# D2522AA register map
Vendor: Dialog; Series: D2522AA; File version: 1.2
CPU: CM0 r1p0, little endian, MPU, FPU, 3 interrupt priority bits
Registers are 32-bit, read-write, reset 0x0 unless marked. A register's access mark holds for its fields unless they carry their own. Offsets are from the block's base; [hi:lo] are bit positions; {n}, {i} and the like mark numbered series; <NAME> marks a mode.

## CRG_TOP — CRG_TOP registers
Base 0x50000000
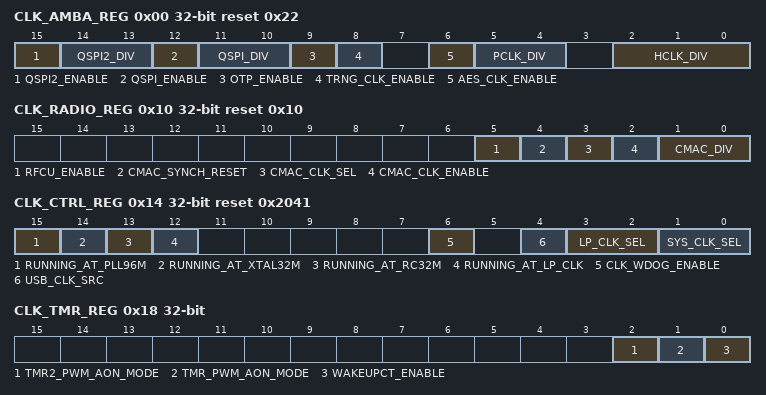
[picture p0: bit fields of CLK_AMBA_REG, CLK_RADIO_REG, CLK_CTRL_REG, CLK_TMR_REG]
0x00 CLK_AMBA_REG reset 0x22 — HCLK, PCLK, divider and clock gates
  [15] QSPI2_ENABLE — Clock enable for QSPI RAM controller
  [14:13] QSPI2_DIV — QSPI divider 00 = divide by 1 01 = divide by 2 10 = divide by 4 11 = divide by 8
  [12] QSPI_ENABLE — Clock enable for QSPI controller
  [11:10] QSPI_DIV — QSPI divider 00 = divide by 1 01 = divide by 2 10 = divide by 4 11 = divide by 8
  [9] OTP_ENABLE — Clock enable for OTP controller
  [8] TRNG_CLK_ENABLE — Clock enable for TRNG block
  [6] AES_CLK_ENABLE — Clock enable for AES crypto block
  [5:4] PCLK_DIV — APB interface clock, Cascaded with HCLK: 00 = divide hclk by 1 01 = divide hclk by 2 10 = divide hclk by 4 11 = divide hclk by 8
  [2:0] HCLK_DIV — AHB interface and microprocessor clock. Source clock divided by: 000 = divide hclk by 1 001 = divide hclk by 2 010 = divide hclk by 4 011 = divide hclk by 8 1xx = divide hclk by 16
0x10 CLK_RADIO_REG reset 0x10 — Radio PLL control register
  [5] RFCU_ENABLE — Enable the RF control Unit clock
  [4] CMAC_SYNCH_RESET — Force synchronous reset to CMAC core and Sleep Timer. Its effective only when both Radio and Timer Power Domains are powered and the clocks are enabled. CMAC CPU and CMAC registers, including the retained ones, will be reset. The 1 should be kept for enough time to make sure that it will be captured by CMAC, Low Power and APB clocks. Should be kept to 1 at least until CM_SLP_SYS_REG->CMAC_RST_BS = 1. To avoid issues with CMAC CPU Debugger its recommended to keep the resetting period short.
  [3] CMAC_CLK_SEL — Selects the clock source 1 = DIV1 clock 0 = DIVN clock
  [2] CMAC_CLK_ENABLE — Enables the clock
  [1:0] CMAC_DIV — Division factor for CMAC 0x0 = divide by 1 0x1 = divide by 2 0x2 = divide by 4 0x3 = divide by 8
0x14 CLK_CTRL_REG reset 0x2041 — Clock control register
  [15] RUNNING_AT_PLL96M ro — Indicates that the PLL96MHz clock is used as clock, and may not be switched off
  [14] RUNNING_AT_XTAL32M ro — Indicates that the XTAL32M clock is used as clock, and may not be switched off
  [13] RUNNING_AT_RC32M ro — Indicates that the RC32M clock is used as clock
  [12] RUNNING_AT_LP_CLK ro — Indicates that either the LP_CLK is being used as clock
  [6] CLK_WDOG_ENABLE — Enables the CLOCK watchdog
  [4] USB_CLK_SRC — Selects the USB source clock 0 : PLL clock, divided by 2 1 : HCLK
  [3:2] LP_CLK_SEL — Sets the clock source of the LowerPower clock 0x0: RC32K 0x1: RCX 0x2: XTAL32K through the oscillator with an external Crystal. 0x3: XTAL32K through an external square wave generator (set PID of GPIO to FUNC_GPIO)
  [1:0] SYS_CLK_SEL — Selects the clock source. 0x0 : XTAL32M 0x1 : RC32M 0x2 : The Low Power clock is used 0x3 : The PLL96Mhz is used
    0=XTAL16M (Selects the XTAL16M as source clock); 1=RC16M (Selects the RC16M as source clock); 2=LP_CLK (Selects the LP_CLK, defined by CLK32K_SOURCE); 3=PLL96M (Selects the PLL96M as source clock)
0x18 CLK_TMR_REG — Clock control for the timers
  [2] TMR2_PWM_AON_MODE — Maps Timer2_pwm onto P1_06. This state is preserved during deep sleep, to allow PWM output on the pad during deep sleep.
  [1] TMR_PWM_AON_MODE — Maps Timer1_pwm onto P1_01 This state is preserved during deep sleep, to allow PWM output on the pad during deep sleep.
  [0] WAKEUPCT_ENABLE — Enables the clock
0x1C CLK_SWITCH2XTAL_REG — Switches clock from RC32M to XTAL32M
  [0] SWITCH2XTAL wo — When writing to this register, the clock switch will happen from RC32M to XTAL32M. If any other clock is selected than RC32M, the selection is discarded.
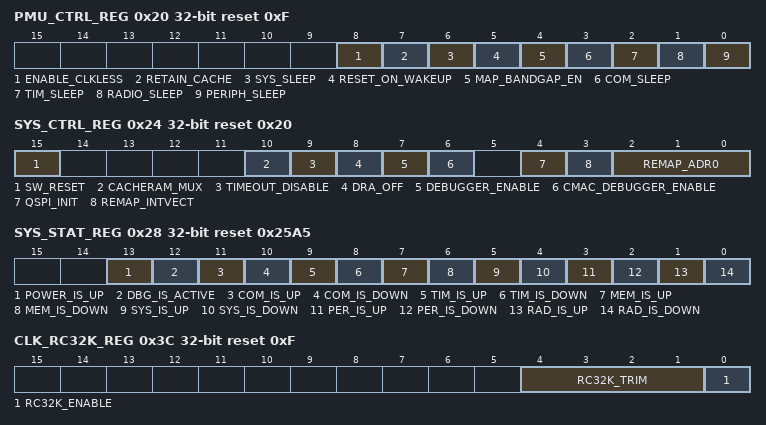
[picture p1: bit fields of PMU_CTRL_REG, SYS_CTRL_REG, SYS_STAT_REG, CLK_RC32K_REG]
0x20 PMU_CTRL_REG reset 0xF — Power Management Unit control register
  [8] ENABLE_CLKLESS — Selects the clockless sleep mode. Wakeup is done asynchronously. When set to '1', the lp_clk is stopped during deep sleep, until a wakeup event (not debounced) is detected by the WAKUPCT block. When set to '0', the lp_clk continues running, so the MAC counters keep on running. This mode cannot be combined with regulated sleep, so keep SLEEP_TIMER=0 when using ENABLE_CLKLESS.
  [7] RETAIN_CACHE — Selects the retainability of the cache block during deep sleep. '1' is retainable, '0' is power gated
  [6] SYS_SLEEP — Put the System powerdomain (PD_SYS) in powerdown. If this bit is '1', and there is no pending IRQ in the PDC for the M33, the PD_SYS will be switched off. Wakeup should be handled by the PDC.
  [5] RESET_ON_WAKEUP — Perform a Hardware Reset after waking up. Booter will be started.
  [4] MAP_BANDGAP_EN — Maps the bandgap_enable to P06
  [3] COM_SLEEP — Put the Communications powerdomain (PD_COM) in powerdown
  [2] TIM_SLEEP — Put the Timers Powerdomain (PD_TIM) in powerdown.
  [1] RADIO_SLEEP — Put the digital part of the radio, including CMAC (PD_RAD) in powerdown
  [0] PERIPH_SLEEP — Put the peripherals power domain (PD_PER) in powerdown
0x24 SYS_CTRL_REG reset 0x20 — System Control register
  [15] SW_RESET wo — Writing a '1' to this bit will generate a SW_RESET.
  [10] CACHERAM_MUX — Controls accessiblity of Cache RAM: 0: the cache controller is bypassed, the cacheRAM is visible in the memory space next to the DataRAMs 1: the cache controller is enabled, the cacheRAM is not visible anymore in the memory space
  [9] TIMEOUT_DISABLE — Disables timeout in Power statemachine. By default, the statemachine continues if after 2 ms the blocks are not started up. This can be read back from ANA_STATUS_REG
  [8] DRA_OFF — Disables the DRA mode, and released the ARM reset
  [7] DEBUGGER_ENABLE — Enable the debugger. This bit is set by the booter according to the OTP header. If not set, the SWDIO and SW_CLK can be used as gpio ports.
  [6] CMAC_DEBUGGER_ENABLE — Enable the CMAC debugger. This bit is set by the booter according to the OTP header. If not set, the SWDIO and SW_CLK can be used as gpio ports.
  [4] QSPI_INIT — Enables QSPI initialization after wakeup
  [3] REMAP_INTVECT — 0: normal operation 1: If ARM is in address range 0 to 0x1FF then the address is remapped to SYS-RAM 0x07FC.0000 to 0x07FC.01FF. This allows to put the interrupt vector table to be placed in RAM while executing from QSPI
  [2:0] REMAP_ADR0 — Controls which memory is located at address 0x0000 for execution. 0x0: ROM 0x1: OTP un-cached 0x2: QSPI FLASH cached 0x3: RAMS un-cached 0x4: QSPI FLASH un-cached (for verification only) 0x5: Reserved 0x6: Cache Data RAM un-cached (CACHERAM_MUX=0, for testing purposes only) Note 1: DWord (64 bits) access is not supported by the Cache Data RAM interface in mirrored mode (only 32, 16 and 8 bits). Note 2: DMA access is not supported by the Cache Data RAM interface when REMAP_ADR0=0x6.
0x28 SYS_STAT_REG reset 0x25A5 — System status register
  [13] POWER_IS_UP ro — Indicates that the Startup statemachine is finished, and all power regulation is in order. In UltraFastWakeup mode, the SW needs to wait for this signal before starting any heavy traffic.
  [12] DBG_IS_ACTIVE ro — Indicates that a debugger is attached.
  [11] COM_IS_UP ro — Indicates that PD_COM is functional
  [10] COM_IS_DOWN ro — Indicates that PD_COM is in power down
  [9] TIM_IS_UP ro — Indicates that PD_TIM is functional
  [8] TIM_IS_DOWN ro — Indicates that PD_TIM is in power down
  [7] MEM_IS_UP ro — Indicates that PD_MEM is functional
  [6] MEM_IS_DOWN ro — Indicates that PD_MEM is power down
  [5] SYS_IS_UP ro — Indicates that PD_PER is functional
  [4] SYS_IS_DOWN ro — Indicates that PD_PER is in power down
  [3] PER_IS_UP ro — Indicates that PD_PER is functional
  [2] PER_IS_DOWN ro — Indicates that PD_PER is in power down
  [1] RAD_IS_UP ro — Indicates that PD_RAD is functional
  [0] RAD_IS_DOWN ro — Indicates that PD_RAD is in power down
0x3C CLK_RC32K_REG reset 0xF — 32 kHz RC oscillator register
  [4:1] RC32K_TRIM — 0000 = lowest frequency 0111 = default 1111 = highest frequency
  [0] RC32K_ENABLE — Enables the 32kHz RC oscillator
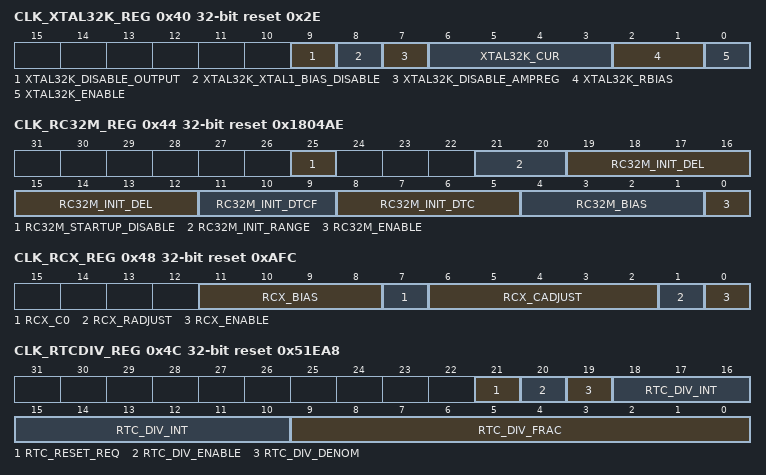
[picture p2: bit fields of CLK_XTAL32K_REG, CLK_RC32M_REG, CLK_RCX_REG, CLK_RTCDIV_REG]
0x40 CLK_XTAL32K_REG reset 0x2E — 32 kHz XTAL oscillator register
  [9] XTAL32K_DISABLE_OUTPUT — Disables output buffer, test only
  [8] XTAL32K_XTAL1_BIAS_DISABLE — Disables the 1nA bias current through the pull down diode
  [7] XTAL32K_DISABLE_AMPREG — Setting this bit disables the amplitude regulation of the XTAL32kHz oscillator. Set this bit to '1' for an external clock to XTAL32Kp Keep this bit '0' with a crystal between XTAL32Kp and XTAL32Km
  [6:3] XTAL32K_CUR — Bias current for the 32kHz XTAL oscillator. 0000 is minimum, 1111 is maximum, 0011 is default. For each application there is an optimal setting for which the start-up behavior is optimal
  [2:1] XTAL32K_RBIAS — Setting for the bias resistor. 00 is maximum, 11 is minimum. Prefered setting will be provided by Dialog
  [0] XTAL32K_ENABLE — Enables the 32kHz XTAL oscillator
0x44 CLK_RC32M_REG reset 0x1804AE — Fast RC control register
  [25] RC32M_STARTUP_DISABLE — Gates the RC32 enable from the startup block. The enable from the clksel and CLK_RC32M_REG[0] are not gated by this bit.
  [21:20] RC32M_INIT_RANGE — Course frequency adjustment
  [19:12] RC32M_INIT_DEL — Fine frequency adjustment
  [11:9] RC32M_INIT_DTCF — Fine duty-cycle adjustment. 0x0: minimum 0x2: default 0x4: maximum
  [8:5] RC32M_INIT_DTC — Course duty-cycle adjustment. 0x0: minimum 0x5: default 0xA: maximum
  [4:1] RC32M_BIAS — Bias adjustment
  [0] RC32M_ENABLE — Enables the 32MHz RC oscillator
0x48 CLK_RCX_REG reset 0xAFC — RCX-oscillator control register
  [11:8] RCX_BIAS — LDO bias current. 0x0: minimum 0xF: maximum
  [7] RCX_C0 — Add unit capacitance to RC-time delay.
  [6:2] RCX_CADJUST — Adjust capacitance part of RC-time delay. 0x00: minimum capacitance 0x1F: maximum capacitance
  [1] RCX_RADJUST — Adjust resistance part of RC-time delay. Lower resistance increases power consumption. 0x0: maximum resistance 0x1: minimum resistance
  [0] RCX_ENABLE — Enable the RCX oscillator
0x4C CLK_RTCDIV_REG reset 0x51EA8 — Divisor for RTC 100Hz clock
  [21] RTC_RESET_REQ — Reset request for the RTC module
  [20] RTC_DIV_ENABLE — Enable for the 100 Hz generation for the RTC block
  [19] RTC_DIV_DENOM — Selects the denominator for the fractional division: 0b0: 1000 0b1: 1024
  [18:10] RTC_DIV_INT — Integer divisor part for RTC 100Hz generation
  [9:0] RTC_DIV_FRAC — Fractional divisor part for RTC 100Hz generation. if RTC_DIV_DENOM=1, <RTC_DIV_FRAC> out of 1024 cycles will divide by <RTC_DIV_INT+1>, the rest is <RTC_DIV_INT> If RTC_DIV_DENOM=0, <RTC_DIV_FRAC> out of 1000 cycles will divide by <RTC_DIV_INT+1>, the rest is <RTC_DIV_INT>
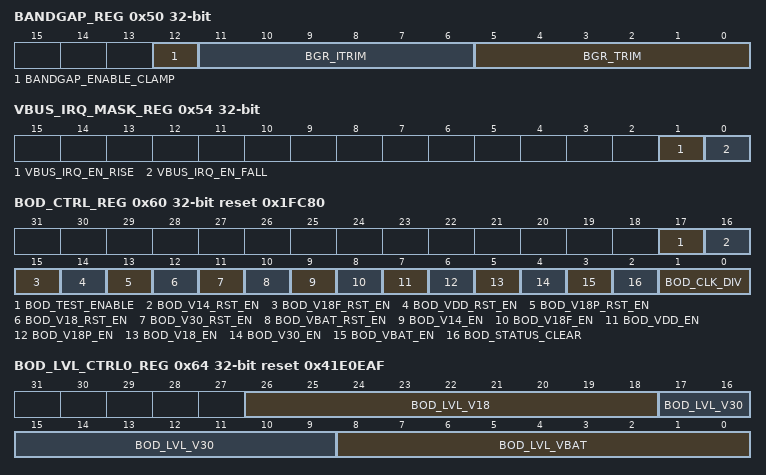
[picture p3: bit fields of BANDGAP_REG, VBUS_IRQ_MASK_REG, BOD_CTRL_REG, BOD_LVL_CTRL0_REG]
0x50 BANDGAP_REG — bandgap trimming
  [12] BANDGAP_ENABLE_CLAMP — Enables a supply clamp inside the bandgap that improves PSRR. Should be enabled by software after cold boot.
  [11:6] BGR_ITRIM — Current trimming for bias
  [5:0] BGR_TRIM — Trim register for bandgap
0x54 VBUS_IRQ_MASK_REG — IRQ masking
  [1] VBUS_IRQ_EN_RISE — Setting this bit to '1' enables VBUS_IRQ generation when the VBUS starts to ramp above threshold
  [0] VBUS_IRQ_EN_FALL — Setting this bit to '1' enables VBUS_IRQ generation when the VBUS starts to fall below threshold
0x58 VBUS_IRQ_CLEAR_REG — Clear pending IRQ register
  [15:0] VBUS_IRQ_CLEAR wo — Writing any value to this register will reset the VBUS_IRQ line
0x60 BOD_CTRL_REG reset 0x1FC80 — Brown Out Detection control register
  [17] BOD_TEST_ENABLE
  [16] BOD_V14_RST_EN — If set, generate power-on reset on channel V14
  [15] BOD_V18F_RST_EN — If set, generate power-on reset on channel V18F
  [14] BOD_VDD_RST_EN — If set, generate power-on reset on channel VDD
  [13] BOD_V18P_RST_EN — If set, generate power-on reset on channel V18P
  [12] BOD_V18_RST_EN — If set, generate power-on reset on channel V18
  [11] BOD_V30_RST_EN — If set, generate power-on reset on channel V30
  [10] BOD_VBAT_RST_EN — If set, generate power-on reset on channel VBAT
  [9] BOD_V14_EN — Enable brown-out detection for channel V14
  [8] BOD_V18F_EN — Enable brown-out detection for channel V18F
  [7] BOD_VDD_EN — Enable brown-out detectionfor channel VDD
  [6] BOD_V18P_EN — Enable brown-out detectio for channel V18P
  [5] BOD_V18_EN — Enable brown-out detectionfor channel V18
  [4] BOD_V30_EN — Enable brown-out detection for channel V30
  [3] BOD_VBAT_EN — Enable brown-out detectionfor channel VBAT
  [2] BOD_STATUS_CLEAR — Clears the brownout status register
  [1:0] BOD_CLK_DIV — Brown-out detector clock divider. 0x0: BOD_CLK/1 0x1: BOD_CLK/2 0x2: BOD_CLK/4 0x3: BOD_CLK/8 (BOD_CLK = 1MHz)
0x64 BOD_LVL_CTRL0_REG reset 0x41E0EAF
  [26:18] BOD_LVL_V18 — Brown-out detection level for V18. VTH_BOD = 1.2 * (BOD_LVL+1)/192
  [17:9] BOD_LVL_V30 — Brown-out detection level for V30. VTH_BOD = 1.2 * (BOD_LVL+1)/192
  [8:0] BOD_LVL_VBAT — Brown-out detection level for VBAT.. VTH_BOD = 1.5*(1.2 * (BOD_LVL+1)/192)
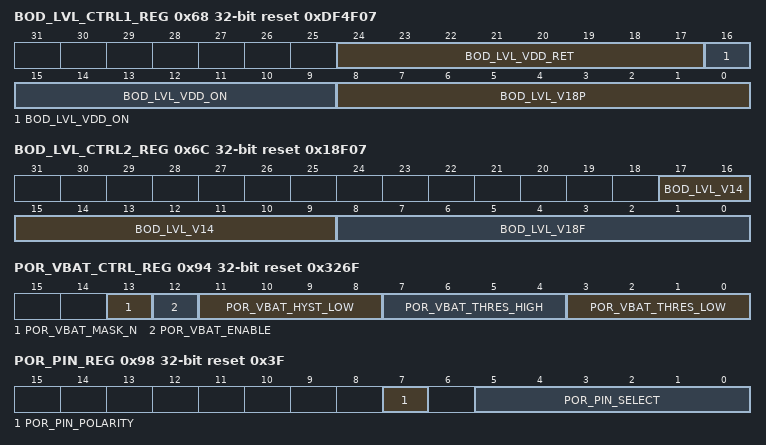
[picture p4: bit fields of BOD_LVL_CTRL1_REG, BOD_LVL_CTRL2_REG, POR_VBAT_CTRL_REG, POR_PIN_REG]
0x68 BOD_LVL_CTRL1_REG reset 0xDF4F07
  [24:17] BOD_LVL_VDD_RET — Brown-out detection level for VDD in sleep. VTH_BOD = 1.2 * (BOD_LVL+1)/192
  [16:9] BOD_LVL_VDD_ON — Brown-out detection level for VDD in active. VTH_BOD = 1.2 * (BOD_LVL+1)/192
  [8:0] BOD_LVL_V18P — Brown-out detection level for V18P. VTH_BOD = 1.2 * (BOD_LVL+1)/192
0x6C BOD_LVL_CTRL2_REG reset 0x18F07
  [17:9] BOD_LVL_V14 — Brown-out detection level for V14 VTH_BOD = 1.2 * (BOD_LVL+1)/192
  [8:0] BOD_LVL_V18F — Brown-out detection level for V18F. VTH_BOD = 1.2 * (BOD_LVL+1)/192
0x70 P0_PAD_LATCH_REG reset 0x7FFFFFFF (reset mask 0x7FFFFFFF) — Control the state retention of the GPIO ports
  [31:0] P0_LATCH_EN — Direct write to the specific pad_latch_enable signal
0x74 P0_SET_PAD_LATCH_REG (reset mask 0x7FFFFFFF) — Control the state retention of the GPIO ports
  [31:0] P0_SET_LATCH_EN rw-once — Direct Set of the marked bits. Reading returns 0x0.
0x78 P0_RESET_PAD_LATCH_REG (reset mask 0x7FFFFFFF) — Control the state retention of the GPIO ports
  [31:0] P0_RESET_LATCH_EN — Direct Reset of the marked bits. Reading returns 0x0.
0x7C P1_PAD_LATCH_REG reset 0x7FFFFF — Control the state retention of the GPIO ports
  [22:0] P1_LATCH_EN — Direct write to the specific pad_latch_enable signal
0x80 P1_SET_PAD_LATCH_REG — Control the state retention of the GPIO ports
  [22:0] P1_SET_LATCH_EN rw-once — Direct Set of the marked bits. Reading returns 0x0.
0x84 P1_RESET_PAD_LATCH_REG — Control the state retention of the GPIO ports
  [22:0] P1_RESET_LATCH_EN — Direct Reset of the marked bits. Reading returns 0x0.
0x90 BOD_STATUS_REG reset not defined
0x94 POR_VBAT_CTRL_REG reset 0x326F — Controls the POR on VBAT
  [13] POR_VBAT_MASK_N — Enables propagation of the generated POR
  [12] POR_VBAT_ENABLE — Enables generation of the POR
  [11:8] POR_VBAT_HYST_LOW — Controls hysteresis of POR. 20mV per step. Must be set to 0x2 when thres_ctrl_low is set to 0xf.
  [7:4] POR_VBAT_THRES_HIGH — High-side (PTAT) threshold contribution: Level --> Threshold 0x0 --> 1.25V 0x1 --> 1.27V 0x2 --> 1.29V 0x3 --> 1.31V 0x4 --> 1.44V 0x5 --> 1.49V 0x6 --> 1.53V 0x7 --> 1.58V 0x8 --> 1.63V 0x9 --> 1.68V 0xA --> 1.73V 0xB --> 1.78V0xC --> 1.83V0xD --> 1.87V0xE --> 1.92V 0xF --> 1.97V
  [3:0] POR_VBAT_THRES_LOW — Low-side (CTAT) threshold contribution Level --> Threshold 0xC --> 1.25V 0xC --> 1.27V 0xC --> 1.29V 0xC --> 1.31V 0x0 --> 1.44V 0x1 --> 1.49V 0x2 --> 1.53V 0x3 --> 1.58V 0x4 --> 1.63V 0x5 --> 1.68V 0x6 --> 1.73V 0x7 --> 1.78V 0x8 --> 1.83V 0x9 --> 1.87V 0xA --> 1.92V 0xB --> 1.97V 0xF --> 1.63V; use only with POR_VBAT_THRES_LOW=0x6 and POR_VBAT_THRES_HYST=0x2
0x98 POR_PIN_REG reset 0x3F — Selects a GPIO pin for POR generation
  [7] POR_PIN_POLARITY — 0: Active Low 1: Active High Note: This applies only for the GPIO pin. Reset pad is always active High
  [5:0] POR_PIN_SELECT — 0x00: P0_00 ... 0x1f: P0_31 0x20: P1_00 ... 0x36: P1_22 0x37 to 0x3E: reserved 0x3F: POR generation disabled
0x9C POR_TIMER_REG reset 0x18 — Time for POR to happen
  [6:0] POR_TIME — Time for the POReset to happen. Formula: Time = POR_TIME x 4096 x RC32 clock period Default value: ~3 seconds
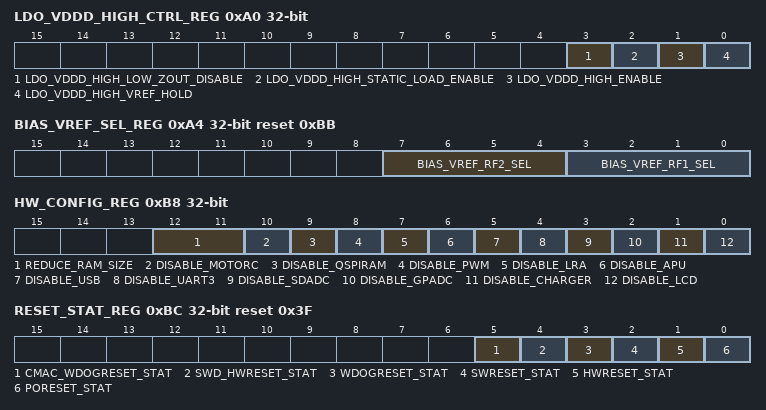
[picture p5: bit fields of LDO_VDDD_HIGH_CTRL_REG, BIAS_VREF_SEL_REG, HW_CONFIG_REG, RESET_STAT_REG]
0xA0 LDO_VDDD_HIGH_CTRL_REG — LDO control register
  [3] LDO_VDDD_HIGH_LOW_ZOUT_DISABLE — Disables the low Zout switch. The low Zout switch pulls the output of the LDO to ground. When 0, the output of the LDO is pulled to ground when the LDO is disabled. When 1, the output of the LDO remains floating when the LDO is disabled.
  [2] LDO_VDDD_HIGH_STATIC_LOAD_ENABLE — Enables a static load of approx. 10 uA at the output of the LDO VDDD_HIGH.
  [1] LDO_VDDD_HIGH_ENABLE — 0: LDO VDDD_HIGH off, 1: LDO VDDD_HIGH on.
  [0] LDO_VDDD_HIGH_VREF_HOLD — 0: Indicates that the reference input is tracked, 1: Indicates that the reference input is sampled.
0xA4 BIAS_VREF_SEL_REG reset 0xBB
  [7:4] BIAS_VREF_RF2_SEL — same as BIAS_VREF_RF1_SEL
  [3:0] BIAS_VREF_RF1_SEL — Vref_code | Vref_Voltage (mV) 0:900 1:930 2:960 3:990 4:1020 5:1050 6:1080 7:1110 8:1140 9:1170 10:1200 11:1230 12:1260 13:1290 14:1320 15:1350
0xB8 HW_CONFIG_REG — Hardware configuration register
  [12:11] REDUCE_RAM_SIZE rw-once — 0x0: no RAM reduction 0x1: remove the last 128 kByte, moving MTB down to RAM6 0x2, 0x3: remove the last 256 kByte, moving MTB down to RAM4
  [10] DISABLE_MOTORC rw-once — Permanently disable Motor Controller Permanently disable the controller enable bit
  [9] DISABLE_QSPIRAM rw-once — Permanently disable QSPI RAM clocks
  [8] DISABLE_PWM rw-once — Permanently disable PWM clocks
  [7] DISABLE_LRA rw-once — Permanently disable LRA/ERM clocks Permanently disable LRA/ERM clocks
  [6] DISABLE_APU rw-once — Permanently disable APU clocks Permanently disable APU blocks
  [5] DISABLE_USB rw-once — Permanently disable the clock of the USB Controller. Permanently disable the charger detect circuit.
  [4] DISABLE_UART3 rw-once — Permanently disable UART3 clock
  [3] DISABLE_SDADC rw-once — Permanently disable ADC2 LDO. Permanently disable ADC2 clock
  [2] DISABLE_GPADC rw-once — Permanently disable ADC LDO. Permanently disable ADC clock.
  [1] DISABLE_CHARGER rw-once — Permanently disable the Charger digital FSM. Keep Analog loop in Hold.
  [0] DISABLE_LCD rw-once — Permanently disable LCD Controller clock Permanently disable LCD Controller block
0xBC RESET_STAT_REG reset 0x3F — Reset status register
  [5] CMAC_WDOGRESET_STAT — Indicates that a CMAC-Watchdog timeout has happened. Note that it is also set when a POReset has happened.
  [4] SWD_HWRESET_STAT — Indicates that a write to SWD_RESET_REG has happened. Note that it is also set when a POReset has happened.
  [3] WDOGRESET_STAT — Indicates that a Watchdog timeout has happened. Note that it is also set when a POReset has happened.
  [2] SWRESET_STAT — Indicates that a SW Reset has happened
  [1] HWRESET_STAT — Indicates that a HW Reset has happened
  [0] PORESET_STAT — Indicates that a PowerOn Reset has happened. All bitfields of RESET_STAT_REG should be read (in order to check the source of reset) and then cleared to '0', allowing thus the HW to automatically set to '1' the proper bitfields during the next reset event.
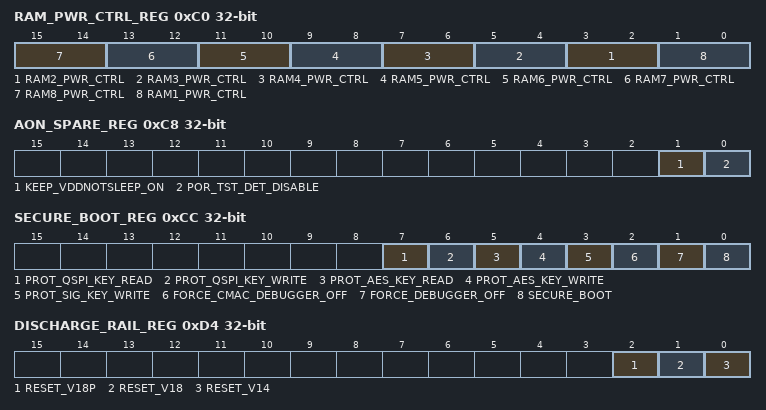
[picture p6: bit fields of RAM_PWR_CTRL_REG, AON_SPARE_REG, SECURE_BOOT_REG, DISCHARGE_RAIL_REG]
0xC0 RAM_PWR_CTRL_REG — Control power state of System RAMS
  [2n-1:2n-2] RAM{n}_PWR_CTRL (n=2..8) — See description of RAM1_PWR_CTRL.
  [1:0] RAM1_PWR_CTRL — Power state control of the individual RAMs. When PD_MEM_IS_UP: 0x0: Normal operation 0x1: Normal operation 0x2: Retained (no access possible) 0x3: Off (memory content corrupted) When PD_MEM_IS_DOWN: 0x0: Retained 0x1: Off (memory content corrupted) 0x2: Retained 0x3: Off (memory content corrupted)
0xC4 LDOS_DISABLE_REG — Force off all LDOs
  [0] LDOS_DISABLE — If set to '1', the following LDOS are disabled: LDO_SUPPLY_VBAT (V33) LDO_SUPPLY_VBUS (V33) LDO_VBAT_RET (V33) LDO_1V8_PA LDO_1V8_PA_RET LDO_1V8_FLASH LDO_1V8_FLASH_RET LDO_CORE (VDD1V2)
0xC8 AON_SPARE_REG — Spare register
  [1] KEEP_VDDNOTSLEEP_ON — If this bit is set to '1', then the VDD_NOTSLEEP is not switched off during sleep. This means higher sleep leakage current.
  [0] POR_TST_DET_DISABLE
0xCC SECURE_BOOT_REG — Controls secure booting
  [7] PROT_QSPI_KEY_READ — This bit will permanently disable CPU read capability at OTP offset 0x00000B00 and for the complete segment
  [6] PROT_QSPI_KEY_WRITE — This bit will permanently disable ANY write capability at OTP offset 0x00000B00 and for the complete segment
  [5] PROT_AES_KEY_READ — This bit will permanently disable CPU read capability at OTP offset 0x00000A00 and for the complete segment
  [4] PROT_AES_KEY_WRITE — This bit will permanently disable ANY write capability at OTP offset 0x00000A00 and for the complete segment
  [3] PROT_SIG_KEY_WRITE — This bit will permanently disable ANY write capability at OTP offset 0x000008C0 and for the complete segment
  [2] FORCE_CMAC_DEBUGGER_OFF — This bit will permanently disable the CMAC debugger
  [1] FORCE_DEBUGGER_OFF — Follows the respective OTP flag value. Its value is updated by the BootROM code. 1: The system debugger SWD is totally disabled. 0: The system debugger is enabled with DEBUGGER_ENABLE
  [0] SECURE_BOOT — Follows the respective OTP flag value. Its value is updated by the BootROM code. 1: system is a secure system supporting secure boot 0: system is not supporting secure boot
0xD4 DISCHARGE_RAIL_REG — Immediate rail resetting. There is no LDO/DCDC gating
  [2] RESET_V18P — 1: Enables immediate discharging of the V18P rail. Note that the source is not disabled. 0: disable immediate discharging of the V18P rail. This bit is ORed with the automatic function controlled by PMU_RESET_RAIL_REG.RESET_V18P
  [1] RESET_V18 — 1: Enables immediate discharging of the V18 rail. Note that the source is not disabled. 0: disable immediate discharging of the V18 rail. This bit is ORed with the automatic function controlled by PMU_RESET_RAIL_REG.RESET_V18
  [0] RESET_V14 — 1: Enables immediate discharging of the V14 rail. Note that the source is not disabled. 0: disable immediate discharging of the V14 rail. This bit is ORed with the automatic function controlled by PMU_RESET_RAIL_REG.RESET_V14
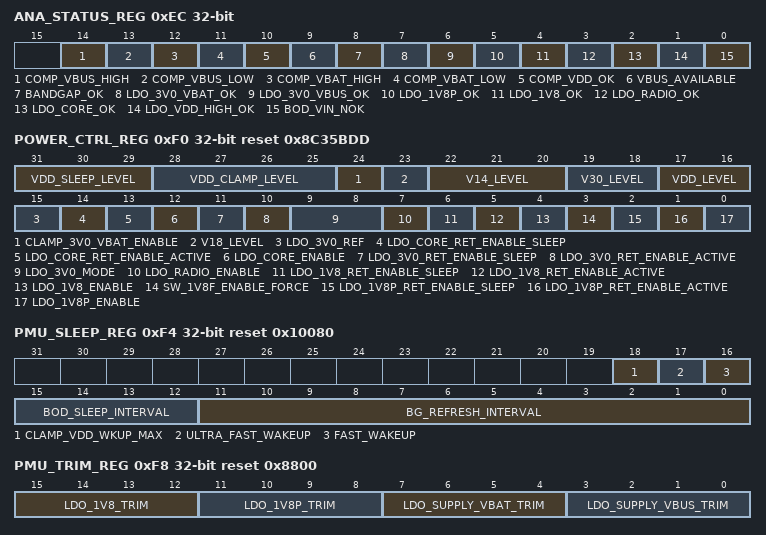
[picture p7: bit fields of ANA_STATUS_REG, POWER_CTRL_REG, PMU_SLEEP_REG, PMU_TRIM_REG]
0xEC ANA_STATUS_REG
  [14] COMP_VBUS_HIGH ro, [13] COMP_VBUS_LOW ro, [12] COMP_VBAT_HIGH ro, [11] COMP_VBAT_LOW ro, [10] COMP_VDD_OK ro, [9] VBUS_AVAILABLE ro, [8] BANDGAP_OK ro, [7] LDO_3V0_VBAT_OK ro, [6] LDO_3V0_VBUS_OK ro, [5] LDO_1V8P_OK ro, [4] LDO_1V8_OK ro, [3] LDO_RADIO_OK ro, [2] LDO_CORE_OK ro, [1] LDO_VDD_HIGH_OK ro, [0] BOD_VIN_NOK ro
0xF0 POWER_CTRL_REG reset 0x8C35BDD (reset mask 0x7FFFFFFF)
  [31:29] VDD_SLEEP_LEVEL — Level setting for VDD rail when using sleep LDO 0x0: 0.75 V 0x1: 0.80 V 0x2: 0.85 V 0x3: 0.90 V 0x4: 0.95 V 0x5: 1.00 V 0x6: N.A. 0x7: N.A.
  [28:25] VDD_CLAMP_LEVEL — Level setting for VDD when using clamp Typical output voltages (not regulated): 0x0: 1037 mV 0x1: 1005 mV 0x2: 978 mV 0x3: 946 mV 0x4: 1120 mV 0x5: 1089 mV 0x6: 1058 mV 0x7: 1030 mV 0x8: 952 mV 0x9: 918 mV 0xA: 889 mV 0xB: 861 mV 0xC: 862 mV 0xD: 828 mV 0xE: 798 mV 0xF: 706 mV ( changed to be lower than ldo_core_ret level)
  [24] CLAMP_3V0_VBAT_ENABLE — Enables (1) or disables (0) clamp that can supply V30 from VBAT
  [23] V18_LEVEL — Level setting for V18 rail 0x0: 1.2 V 0x1: 1.8 V
  [22:20] V14_LEVEL — Level setting for V14 rail 0x0: 1.20 V 0x1: 1.25 V 0x2: 1.30 V 0x3: 1.35 V 0x4: 1.40 V 0x5: 1.45 V 0x6: 1.50 V 0x7: 1.55 V
  [19:18] V30_LEVEL — Level setting for V30 rail 0x0: 3.0 V 0x1: 3.45 V 0x2: 3.3 V 0x3: 3.3 V
  [17:16] VDD_LEVEL — Level setting for VDD rail 0x0: 0.9 V 0x1: 1.0 V 0x2: 1.1 V 0x3: 1.2 V
  [15] LDO_3V0_REF — Selects reference source for V30 LDOs 0x0: VDD rail 0x1: Bandgap output
  [14] LDO_CORE_RET_ENABLE_SLEEP — Enables (1) or disables (0) LDO_CORE_RET in sleep mode
  [13] LDO_CORE_RET_ENABLE_ACTIVE — Enables (1) or disables (0) LDO_CORE_RET in active mode
  [12] LDO_CORE_ENABLE — Enables (1) or disables (0) LDO_CORE
  [11] LDO_3V0_RET_ENABLE_SLEEP — Enables (1) or disables (0) LDO_3V0_RET in sleep mode
  [10] LDO_3V0_RET_ENABLE_ACTIVE — Enables (1) or disables (0) LDO_3V0_RET in active mode
  [9:8] LDO_3V0_MODE — Controls for LDO_3V0 0x0: Disabled 0x1: LDO_VBAT enabled 0x2: LDO_VBUS enabled 0x3: Automatic selection of LDO_VBAT or LDO_VBUS
  [7] LDO_RADIO_ENABLE — Enables (1) or disables (0) LDO_RADIO
  [6] LDO_1V8_RET_ENABLE_SLEEP — Enables (1) or disables (0) LDO_1V8_RET in sleep mode
  [5] LDO_1V8_RET_ENABLE_ACTIVE — Enables (1) or disables (0) LDO_1V8_RET in active mode
  [4] LDO_1V8_ENABLE — Enables (1) or disables (0) LDO_1V8
  [3] SW_1V8F_ENABLE_FORCE — Forces switch between V18P and V18F rails on
  [2] LDO_1V8P_RET_ENABLE_SLEEP — Enables (1) or disables (0) LDO_1V8P_RET in sleep mode
  [1] LDO_1V8P_RET_ENABLE_ACTIVE — Enables (1) or disables (0) LDO_1V8P_RET in active mode
  [0] LDO_1V8P_ENABLE — Enables (1) or disables (0) LDO_1V8P
0xF4 PMU_SLEEP_REG reset 0x10080
  [18] CLAMP_VDD_WKUP_MAX — Forces the VDD clamp voltage to its maximum value when waking up from sleep.
  [17] ULTRA_FAST_WAKEUP — Allows the core to start running on the RC32M while the PMU is still waiting for supplies to settle to the final value. Only use in combination with FAST_WAKEUP and 0.9 V on VDD during sleep.
  [16] FAST_WAKEUP — Speeds up the wakeup process by enabling all LDOs simultaneously instead of in staggered order. Only use if all voltages have been retained during sleep.
  [15:12] BOD_SLEEP_INTERVAL — This is a value defining the interval every which Brown Out Detection is activated to check on the power rails voltage. The value represents BG_REFRESH_INTERVALs
  [11:0] BG_REFRESH_INTERVAL — This is a value defining the interval every which the Bandgap will be activated for refresh. The value represents ticks of lp_clk/64 e.g. 30,5 us * 64 = 1,9 ms.
0xF8 PMU_TRIM_REG reset 0x8800
  [15:12] LDO_1V8_TRIM — Trim setting for LDO_1V8 Unsigned binary notation, trim range ±10 %
  [11:8] LDO_1V8P_TRIM — Trim setting for LDO_1V8P Unsigned binary notation, trim range ±10 %
  [7:4] LDO_SUPPLY_VBAT_TRIM — Trim setting for LDO_SUPPLY_VBUS Sign-magnitude notation, trim range ±10 %
  [3:0] LDO_SUPPLY_VBUS_TRIM — Trim setting for LDO_SUPPLY_VBAT Sign-magnitude notation, trim range ±10 %
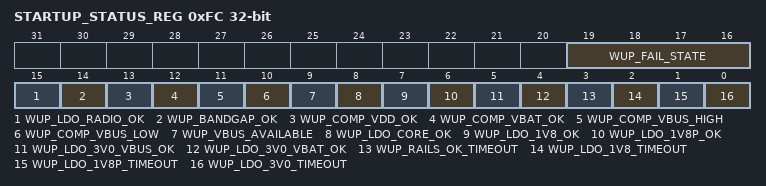
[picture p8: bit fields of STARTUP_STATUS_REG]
0xFC STARTUP_STATUS_REG
  [19:16] WUP_FAIL_STATE ro — Shows state of startup FSM at the moment force_running was asserted
  [15] WUP_LDO_RADIO_OK ro — LDO_RADIO_OK value at time of LDO_CORE_RADIO state Only set if force_running is asserted
  [14] WUP_BANDGAP_OK ro — BANDGAP_OK value at time of RAILS_OK state Only set if force_running is asserted
  [13] WUP_COMP_VDD_OK ro — COMP_VDD_OK value at time of LDO_CORE_RADIO state Only set if force_running is asserted
  [12] WUP_COMP_VBAT_OK ro — COMP_VBAT_LOW value at time of RAILS_OK state Only set if force_running is asserted
  [11] WUP_COMP_VBUS_HIGH ro — COMP_VBUS_HIGH value at time of RAILS_OK state Only set if force_running is asserted
  [10] WUP_COMP_VBUS_LOW ro — COMP_VBUS_LOW value at time of RAILS_OK state Only set if force_running is asserted
  [9] WUP_VBUS_AVAILABLE ro — VBUS_AVAILABLE value at time of LDO_3V0 state Only set if force_running is asserted
  [8] WUP_LDO_CORE_OK ro — LDO_CORE_OK value at time of LDO_CORE_RADIO state Only set if force_running is asserted
  [7] WUP_LDO_1V8_OK ro — LDO_1V8_OK value at time of LDO_1V8 state Only set if force_running is asserted
  [6] WUP_LDO_1V8P_OK ro — LDO_1V8P_OK value at time of LDO_1V8P state Only set if force_running is asserted
  [5] WUP_LDO_3V0_VBUS_OK ro — LDO_3V0_VBUS_OK value at time of LDO_3V0 state Only set if force_running is asserted
  [4] WUP_LDO_3V0_VBAT_OK ro — LDO_3V0_VBAT_OK value at time of LDO_3V0 state Only set if force_running is asserted
  [3] WUP_RAILS_OK_TIMEOUT ro — High if RAILS_OK state timed out, set when FSM reaches running state
  [2] WUP_LDO_1V8_TIMEOUT ro — High if LDO_1V8 state timed out, set when FSM reaches running state
  [1] WUP_LDO_1V8P_TIMEOUT ro — High if LDO_1V8P state timed out, set when FSM reaches running state
  [0] WUP_LDO_3V0_TIMEOUT ro — High if LDO_3V0 state timed out, set when FSM reaches running state
